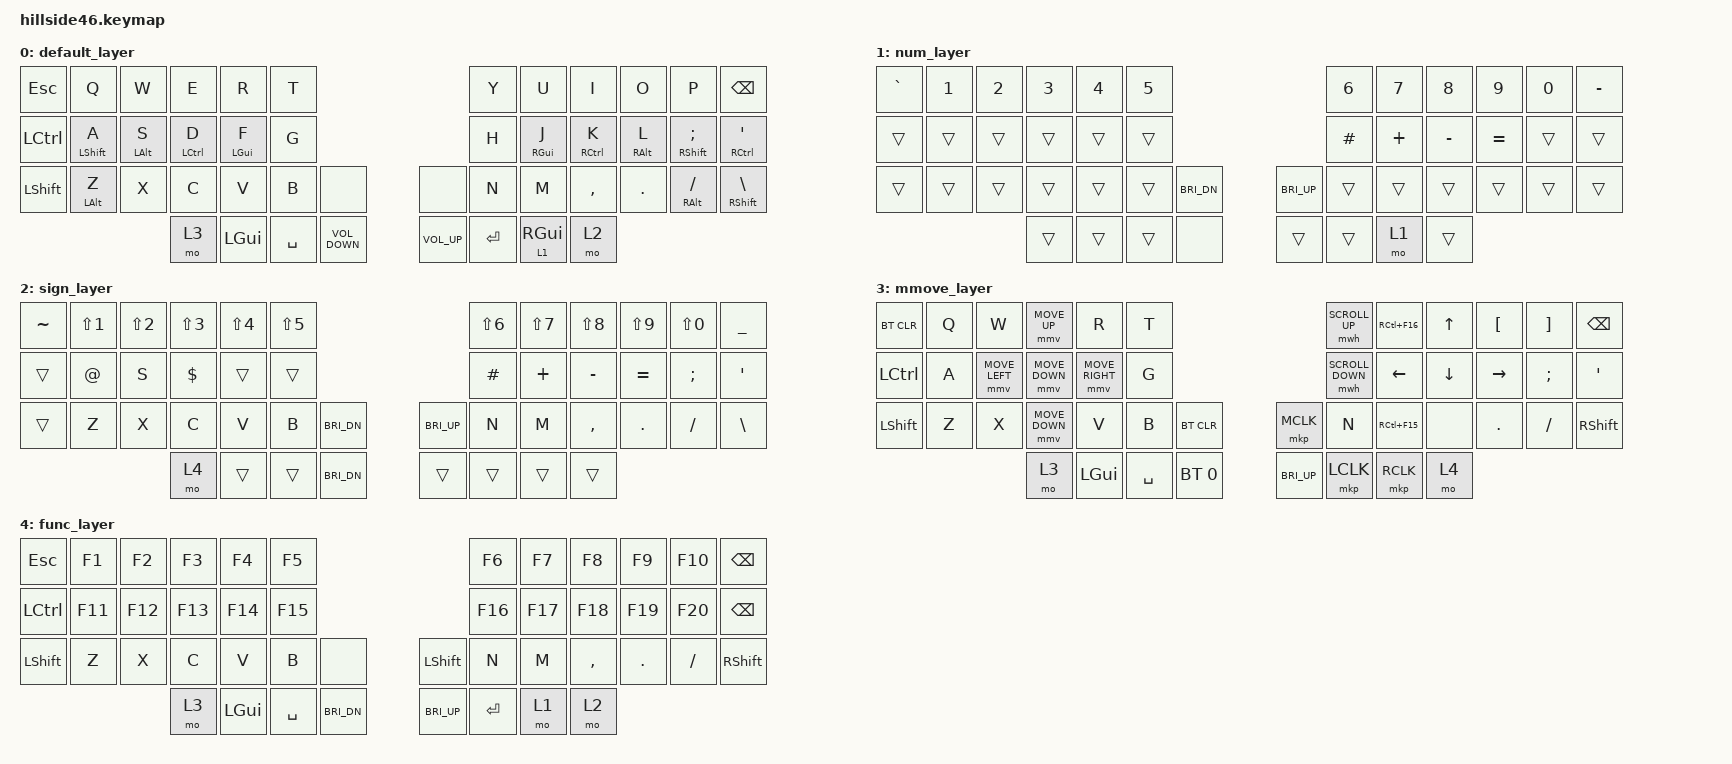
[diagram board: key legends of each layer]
/*
 * Copyright (c) 2021-2022 The ZMK Contributors
 *
 * SPDX-License-Identifier: MIT
 */

/*
 * ZMK Keymap Editor: https://nickcoutsos.github.io/keymap-editor/
 */

#include <behaviors.dtsi>
#include <dt-bindings/zmk/keys.h>
#include <dt-bindings/zmk/bt.h>
#include <dt-bindings/zmk/outputs.h>
#include <dt-bindings/zmk/mouse.h>

#define DEFAULT 0
#define NUM     1
#define SIGN    2
#define MMOVE   3

#define U_MOUSE_MOVE_MAX 1800                    /* <--- New max speed setting (default: 600) */
#undef MOVE_UP
#undef MOVE_DOWN
#undef MOVE_LEFT
#undef MOVE_RIGHT
#define MOVE_UP MOVE_VERT(-U_MOUSE_MOVE_MAX)
#define MOVE_DOWN MOVE_VERT(U_MOUSE_MOVE_MAX)
#define MOVE_LEFT MOVE_HOR(-U_MOUSE_MOVE_MAX)
#define MOVE_RIGHT MOVE_HOR(U_MOUSE_MOVE_MAX)

&mmv {
    acceleration-exponent = <2>;
    time-to-max-speed-ms = <500>;
    delay-ms = <20>;
};

#define U_MOUSE_SCROLL_MAX 25                    /* <--- New max speed setting (default: 10) */

#undef SCROLL_UP
#undef SCROLL_DOWN
#undef SCROLL_LEFT
#undef SCROLL_RIGHT
#define SCROLL_UP SCROLL_VERT(U_MOUSE_SCROLL_MAX)
#define SCROLL_DOWN SCROLL_VERT(-U_MOUSE_SCROLL_MAX)
#define SCROLL_LEFT SCROLL_HOR(-U_MOUSE_SCROLL_MAX)
#define SCROLL_RIGHT SCROLL_HOR(U_MOUSE_SCROLL_MAX)

&mwh {
  time-to-max-speed-ms = <500>;                 /* <--- How long time until max speed is reached */
};

/ {
    behaviors {
        gqt: global-quick-tap {
            compatible = "zmk,behavior-hold-tap";
            label = "GLOBAL_QUICK_TAP";
            #binding-cells = <2>;
            flavor = "tap-preferred";
            tapping-term-ms = <200>;
            quick-tap-ms = <200>;
            global-quick-tap;
            bindings = <&kp>, <&kp>;
        };
    };
    
    keymap {
        compatible = "zmk,keymap";

        default_layer {
            // DEFAULT 0                         
            // ---------------------------------------------------------------------------------------------------------------------------------
            // |  ESC  |  Q  |  W  |  E   |  R   |  T   |                                          |  Y   |  U    |  I    |  O   |   P   |  BS  |
            // |  CTRL |  A  |  S  |  D   |  F   |  G   |                                          |  H   |  J    |  K    |  L   |   ;   |   '  |
            // | SHFT |  Z  |  X  |  C   |  V   |  B   |   none  |                      |  none   |  N   |  M    |  ,   |  .    |   /   |   \  |
            //                            | MO 3  | LGUI  |  SPACE  | VOL↓ |    | VOL↑|  ENTER  | LT 1 RGUI | MO 2   | 
            bindings = <
                &kp ESC   &kp Q &kp W &kp E &kp R &kp T                                            &kp Y      &kp U  &kp I     &kp O   &kp P            &kp BACKSPACE
                &kp LCTRL &gqt LSHFT A &gqt LALT S &gqt LCTRL D &gqt LGUI F &kp G                 &kp H      &gqt RGUI J  &gqt RCTRL K  &gqt RALT L   &gqt RSHFT SEMI &gqt RCTRL SQT
                &kp LSHFT &gqt LALT Z &kp X &kp C &kp V &kp B &none             &none     &kp N      &kp M  &kp COMMA &kp DOT &gqt RALT FSLH &gqt RSHFT BACKSLASH
                &mo 3 &kp LGUI &kp SPACE &kp C_VOLUME_DOWN          &kp C_VOLUME_UP &kp ENTER &lt 1 RGUI &mo 2
            >;
        };

        num_layer {
            // NUM	1
            // ---------------------------------------------------------------------------------------------------------------------------------
            // |    `   |  1  |  2  |  3   |  4   |  5   |                                          |  6   |  7    |  8    |  9   |   0   |   -  |
            // |       |     |     |      |      |      |                                          |  #   |  +    |  -    |  =   |       |      |
            // |       |     |     |      |      |      |        |                        |        |      |       |       |      |       |      |
            //                            |      |      |        |      |        |        |        | MO 1 |       | 
            bindings = <
                &kp GRAVE &kp N1 &kp N2 &kp N3 &kp N4 &kp N5                                        &kp N6      &kp N7    &kp N8     &kp N9     &kp N0   &kp MINUS
                &trans &trans &trans &trans &trans &trans                                        &kp HASH   &kp PLUS   &kp MINUS  &kp EQUAL  &trans &trans
                &trans &trans &trans &trans &trans &trans  &kp C_BRI_DN                          &kp C_BRI_UP &trans &trans  &trans &trans &trans &trans
                &trans &trans  &trans  &none      &trans  &trans &mo 1  &trans 
            >;
        };

        sign_layer {
            // SIGN 2
            // ---------------------------------------------------------------------------------------------------------------------------------
            // |  ~  |  !  |  @  |  #   |  $   |  %   |                                               |  ^   |  &    |  *    |  (   |   )   |  _ |
            // |       |  @  |     |  $   |      |     |                                                |  #   |  +    |  -    |  =   |   ;   |   '|
            // |       |     |     |      |      |     |    |      |                       |         |  *   |  /    |  <    |  >   |   /   | \  |
            //                            |      |     |         |         |      |        |         |      |       |
            bindings = <
                &kp TILDE &kp LS(N1) &kp LS(N2) &kp LS(N3) &kp LS(N4) &kp LS(N5)        &kp LS(N6) &kp LS(N7) &kp LS(N8) &kp LS(N9) &kp LS(N0)  &kp UNDERSCORE
                &trans &kp AT     &kp S   &kp DOLLAR &trans     &trans             &kp HASH   &kp PLUS   &kp MINUS  &kp EQUAL  &kp SEMI &kp SQT
                &trans &kp Z &kp X &kp C &kp V &kp B &kp C_BRI_DN                          &kp C_BRI_UP &kp N &kp M  &kp COMMA &kp DOT &kp FSLH &kp BACKSLASH
                &mo 4   &trans &trans  &kp C_BRI_DN        &trans &trans &trans  &trans
            >;
        };
        
        mmove_layer {
            // MMOVE 3
            // ---------------------------------------------------------------------------------------------------------------------------------
            // |ESC|  Q  |  W  |  &mmv MOVE_UP   |  R   |  T   |                                          |  &mwh SCROLL_VERT(-40)  |  U  |  UP    |   [  |   ]  |  BS  |
            // |  CTRL  |  A | &mmv MOVE_LEFT | &mmv MOVE_DOWN | &mmv MOVE_RIGHT | G |             |  &mwh SCROLL_VERT(40)  |  LEFT |  DOWN  | RIGHT |   ;   |   '  |
            // |   LSHIFT  |  Z   |  X   |  C    |      |      |  BT CLEAR |                           |     |    |  N   |  &mmv MOVE_LEFT | &mmv MOVE_RIGHT |  .   |   /   | CTRL |
            //                            |       |     |     |    BT 0  |         |        |         |      |       |
            bindings = <
                &bt BT_CLR &kp Q &kp W &mmv MOVE_UP &kp R &kp T                     		&mwh SCROLL_UP  &kp RC(F16)  &kp UP     &kp LEFT_BRACKET  &kp RIGHT_BRACKET   &kp BACKSPACE
                &kp LCTRL &kp A &mmv MOVE_LEFT &mmv MOVE_DOWN &mmv MOVE_RIGHT &kp G		&mwh SCROLL_DOWN   &kp LEFT  &kp DOWN  &kp RIGHT   &kp SEMI &kp SQT
                &kp LSHFT &kp Z &kp X &mmv MOVE_DOWN &kp V &kp B &bt BT_CLR                  &mkp MCLK &kp N &kp RC(F15) &none &kp DOT &kp FSLH &kp RSHFT
                &mo 3 &kp LGUI   &kp SPACE  &bt BT_SEL 0      &kp C_BRI_UP  &mkp LCLK &mkp RCLK  &mo 4
            >;
        };

        func_layer {
            // FUNC 4
            // ---------------------------------------------------------------------------------------------------------------------------------
            // |        |  F1  |  F2  |  F3   |  F4   |  F5   |                                          |  F6   |  F7    |  F8    |  F9  |   F10  |  BS  |
            // |  CTRL  |  F11  | F12  | F13  | F14   |  F15   |                                          |  F16   | F17 |  F18  | F19 |   F20   |   BS  |
            // | SHFT  |  Z  |  X  |  C   |  V   |  B   | none |                |         |   N   |  M    |  ,    |  .   |   /   | RSHFT |
            //                      |      |      |      |  Brighter   |                        | Darker |  ENTER  |  MO1  | MO2  |
            bindings = <
                &kp ESC &kp F1 &kp F2 &kp F3 &kp F4 &kp F5                                                &kp F6 &kp F7 &kp F8 &kp F9 &kp F10 &kp BACKSPACE
                &kp LCTRL &kp F11 &kp F12 &kp F13 &kp F14 &kp F15                                                &kp F16 &kp F17 &kp F18 &kp F19 &kp F20 &kp BACKSPACE
                &kp LSHFT &kp Z &kp X &kp C &kp V &kp B &none                            &kp LSHFT &kp N &kp M  &kp COMMA &kp DOT &kp FSLH &kp RSHFT
                &mo 3 &kp LGUI &kp SPACE  &kp C_BRI_DN          &kp C_BRI_UP  &kp ENTER &mo 1  &mo 2
            >;
        };
    };
};
